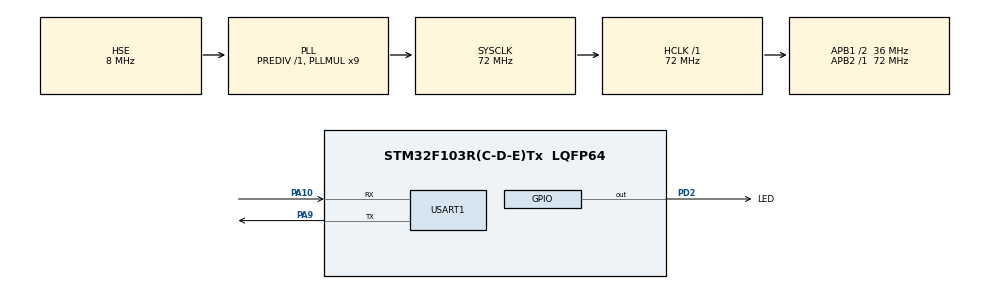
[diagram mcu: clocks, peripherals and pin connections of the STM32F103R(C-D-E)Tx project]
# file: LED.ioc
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FREERTOS.Tasks01=Task1,24,128,Task01,Default,NULL,Dynamic,NULL,NULL;Task2,8,128,Task02,Default,NULL,Dynamic,NULL,NULL
Mcu.Family=STM32F1
Mcu.Name=STM32F103R(C-D-E)Tx
Mcu.Package=LQFP64
NVIC.PriorityGroup=NVIC_PRIORITYGROUP_4
NVIC.TIM1_UP_IRQn=true\:0\:0\:false\:false\:true\:false\:false\:true
NVIC.TimeBase=TIM1_UP_IRQn
NVIC.TimeBaseIP=TIM1
PA10.Mode=Asynchronous
PA10.Signal=USART1_RX
PA13.Mode=Serial_Wire
PA13.Signal=SYS_JTMS-SWDIO
PA14.Mode=Serial_Wire
PA14.Signal=SYS_JTCK-SWCLK
PA9.Mode=Asynchronous
PA9.Signal=USART1_TX
PC14-OSC32_IN.Mode=LSE-External-Oscillator
PC14-OSC32_IN.Signal=RCC_OSC32_IN
PC15-OSC32_OUT.Mode=LSE-External-Oscillator
PC15-OSC32_OUT.Signal=RCC_OSC32_OUT
PD0-OSC_IN.Mode=HSE-External-Oscillator
PD0-OSC_IN.Signal=RCC_OSC_IN
PD1-OSC_OUT.Mode=HSE-External-Oscillator
PD1-OSC_OUT.Signal=RCC_OSC_OUT
PD2.GPIO_Label=LED
PD2.GPIO_Speed=GPIO_SPEED_FREQ_HIGH
PD2.PinState=GPIO_PIN_SET
PD2.Signal=GPIO_Output
ProjectManager.HeapSize=0x200
ProjectManager.StackSize=0x400
ProjectManager.TargetToolchain=STM32CubeIDE
RCC.AHBFreq_Value=72000000
RCC.APB1CLKDivider=RCC_HCLK_DIV2
RCC.APB1Freq_Value=36000000
RCC.APB1TimFreq_Value=72000000
RCC.APB2Freq_Value=72000000
RCC.APB2TimFreq_Value=72000000
RCC.HCLKFreq_Value=72000000
RCC.PLLMUL=RCC_PLL_MUL9
RCC.PLLSourceVirtual=RCC_PLLSOURCE_HSE
RCC.SYSCLKFreq_VALUE=72000000
RCC.SYSCLKSource=RCC_SYSCLKSOURCE_PLLCLK
RCC.USBFreq_Value=72000000
USART1.VirtualMode=VM_ASYNC
VP_FREERTOS_VS_CMSIS_V2.Mode=CMSIS_V2
VP_SYS_VS_tim1.Mode=TIM1
board=custom

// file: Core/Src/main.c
/* USER CODE BEGIN Header */
/**
  ******************************************************************************
  * @file           : main.c
  * @brief          : Main program body
  ******************************************************************************
  * @attention
  *
  * <h2><center>&copy; Copyright (c) 2021 STMicroelectronics.
  * All rights reserved.</center></h2>
  *
  * This software component is licensed by ST under Ultimate Liberty license
  * SLA0044, the "License"; You may not use this file except in compliance with
  * the License. You may obtain a copy of the License at:
  *                             www.st.com/SLA0044
  *
  ******************************************************************************
  */
/* USER CODE END Header */
#include "main.h"
#include "cmsis_os.h"

/* USER CODE BEGIN Includes */
#include <stdio.h>

/* USER CODE END Includes */

/* USER CODE BEGIN PM */
int ss=0;
/* USER CODE END PM */

UART_HandleTypeDef huart1;

/* Definitions for Task1 */
osThreadId_t Task1Handle;
const osThreadAttr_t Task1_attributes = {
  .name = "Task1",
  .stack_size = 128 * 4,
  .priority = (osPriority_t) osPriorityNormal,
};
/* Definitions for Task2 */
osThreadId_t Task2Handle;
const osThreadAttr_t Task2_attributes = {
  .name = "Task2",
  .stack_size = 128 * 4,
  .priority = (osPriority_t) osPriorityLow,
};

void SystemClock_Config(void);
static void MX_GPIO_Init(void);
static void MX_USART1_UART_Init(void);
void Task01(void *argument);
void Task02(void *argument);

/* USER CODE BEGIN 0 */
#ifdef __GNUC__
#define PUTCHAR_PROTOTYPE int __io_putchar(int ch)
#else
#define PUTCHAR_PROTOTYPE int fputc(int ch, FILE *f)
#endif

PUTCHAR_PROTOTYPE
{
//同样USART2改为你的串口
	HAL_UART_Transmit(&huart1, (uint8_t*)&ch,1,HAL_MAX_DELAY);
    return ch;
}
/* USER CODE END 0 */

int main(void)
{

  /* MCU Configuration--------------------------------------------------------*/

  /* Reset of all peripherals, Initializes the Flash interface and the Systick. */
  HAL_Init();

  /* Configure the system clock */
  SystemClock_Config();

  /* Initialize all configured peripherals */
  MX_GPIO_Init();
  MX_USART1_UART_Init();

  /* Init scheduler */
  osKernelInitialize();

  /* Create the thread(s) */
  /* creation of Task1 */
  Task1Handle = osThreadNew(Task01, NULL, &Task1_attributes);

  /* creation of Task2 */
  Task2Handle = osThreadNew(Task02, NULL, &Task2_attributes);

  /* Start scheduler */
  osKernelStart();

  /* We should never get here as control is now taken by the scheduler */
  /* Infinite loop */
  while (1)
  {

  }
}

void SystemClock_Config(void)
{
  RCC_OscInitTypeDef RCC_OscInitStruct = {0};
  RCC_ClkInitTypeDef RCC_ClkInitStruct = {0};

  /** Initializes the RCC Oscillators according to the specified parameters
  * in the RCC_OscInitTypeDef structure.
  */
  RCC_OscInitStruct.OscillatorType = RCC_OSCILLATORTYPE_HSE;
  RCC_OscInitStruct.HSEState = RCC_HSE_ON;
  RCC_OscInitStruct.HSEPredivValue = RCC_HSE_PREDIV_DIV1;
  RCC_OscInitStruct.HSIState = RCC_HSI_ON;
  RCC_OscInitStruct.PLL.PLLState = RCC_PLL_ON;
  RCC_OscInitStruct.PLL.PLLSource = RCC_PLLSOURCE_HSE;
  RCC_OscInitStruct.PLL.PLLMUL = RCC_PLL_MUL9;
  if (HAL_RCC_OscConfig(&RCC_OscInitStruct) != HAL_OK)
  {
    Error_Handler();
  }
  /** Initializes the CPU, AHB and APB buses clocks
  */
  RCC_ClkInitStruct.ClockType = RCC_CLOCKTYPE_HCLK|RCC_CLOCKTYPE_SYSCLK
                              |RCC_CLOCKTYPE_PCLK1|RCC_CLOCKTYPE_PCLK2;
  RCC_ClkInitStruct.SYSCLKSource = RCC_SYSCLKSOURCE_PLLCLK;
  RCC_ClkInitStruct.AHBCLKDivider = RCC_SYSCLK_DIV1;
  RCC_ClkInitStruct.APB1CLKDivider = RCC_HCLK_DIV2;
  RCC_ClkInitStruct.APB2CLKDivider = RCC_HCLK_DIV1;

  if (HAL_RCC_ClockConfig(&RCC_ClkInitStruct, FLASH_LATENCY_2) != HAL_OK)
  {
    Error_Handler();
  }
}

static void MX_USART1_UART_Init(void)
{

  huart1.Instance = USART1;
  huart1.Init.BaudRate = 115200;
  huart1.Init.WordLength = UART_WORDLENGTH_8B;
  huart1.Init.StopBits = UART_STOPBITS_1;
  huart1.Init.Parity = UART_PARITY_NONE;
  huart1.Init.Mode = UART_MODE_TX_RX;
  huart1.Init.HwFlowCtl = UART_HWCONTROL_NONE;
  huart1.Init.OverSampling = UART_OVERSAMPLING_16;
  if (HAL_UART_Init(&huart1) != HAL_OK)
  {
    Error_Handler();
  }

}

static void MX_GPIO_Init(void)
{
  GPIO_InitTypeDef GPIO_InitStruct = {0};

  /* GPIO Ports Clock Enable */
  __HAL_RCC_GPIOC_CLK_ENABLE();
  __HAL_RCC_GPIOD_CLK_ENABLE();
  __HAL_RCC_GPIOA_CLK_ENABLE();

  /*Configure GPIO pin Output Level */
  HAL_GPIO_WritePin(LED_GPIO_Port, LED_Pin, GPIO_PIN_SET);

  /*Configure GPIO pin : LED_Pin */
  GPIO_InitStruct.Pin = LED_Pin;
  GPIO_InitStruct.Mode = GPIO_MODE_OUTPUT_PP;
  GPIO_InitStruct.Pull = GPIO_NOPULL;
  GPIO_InitStruct.Speed = GPIO_SPEED_FREQ_HIGH;
  HAL_GPIO_Init(LED_GPIO_Port, &GPIO_InitStruct);

}

void Task01(void *argument)
{
  /* USER CODE BEGIN 5 */
  /* Infinite loop */
  for(;;)
  {
	  //HAL_GPIO_WritePin(GPIOD, GPIO_Pin_2, GPIO_PIN_SET);
	  HAL_GPIO_TogglePin(GPIOD, GPIO_PIN_2);
	  ss++;
	  osDelay(500);

  }
  /* USER CODE END 5 */
}

void Task02(void *argument)
{
  /* USER CODE BEGIN Task02 */
  /* Infinite loop */
  for(;;)
  {
	 if(ss==2)
	 {
		 ss=0;

		 //HAL_UART_Transmit(&huart1, 'a',2,0xffff);
	 }
	 printf("hello!\r\n");
	 osDelay(500);

  }
  /* USER CODE END Task02 */
}

 /**
  * @brief  Period elapsed callback in non blocking mode
  * @note   This function is called  when TIM1 interrupt took place, inside
  * HAL_TIM_IRQHandler(). It makes a direct call to HAL_IncTick() to increment
  * a global variable "uwTick" used as application time base.
  * @param  htim : TIM handle
  * @retval None
  */
void HAL_TIM_PeriodElapsedCallback(TIM_HandleTypeDef *htim)
{
  if (htim->Instance == TIM1) {
    HAL_IncTick();
  }
}

void Error_Handler(void)
{
  __disable_irq();
  while (1)
  {
  }
}

/************************ (C) COPYRIGHT STMicroelectronics *****END OF FILE****/
